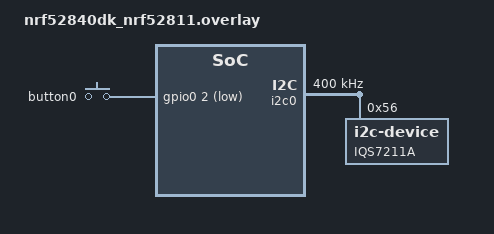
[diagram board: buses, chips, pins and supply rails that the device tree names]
// To get started, press Ctrl+Space to bring up the completion menu and view the available nodes.

// You can also use the buttons in the sidebar to perform actions on nodes.
// Actions currently available include:

// * Enabling / disabling the node
// * Adding the bus to a bus
// * Removing the node
// * Connecting ADC channels

// For more help, browse the DeviceTree documentation at https: //docs.zephyrproject.org/latest/guides/dts/index.html
// You can also visit the nRF DeviceTree extension documentation at https: //docs.nordicsemi.com/bundle/nrf-connect-vscode/page/guides/ncs_configure_app.html#devicetree-support-in-the-extension

&i2c0 {
  status = "okay";
  clock-frequency = <I2C_BITRATE_FAST>;
  iqs7211a: iqs7211a@56 {
    compatible = "i2c-device";
    reg = <0x56>;
    label = "IQS7211A";
  };
};

&button0 {
  gpios = <&gpio0 2 GPIO_ACTIVE_LOW>;
};
